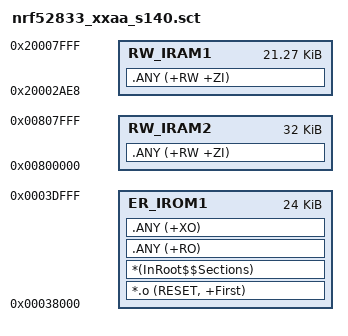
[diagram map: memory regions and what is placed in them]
; *************************************************************
; *** Scatter-Loading Description File generated by uVision ***
; *************************************************************

LR_IROM1 0x00038000 0x00006000  {    ; load region size_region
  ER_IROM1 0x00038000 0x00006000  {  ; load address = execution address
   *.o (RESET, +First)
   *(InRoot$$Sections)
   .ANY (+RO)
   .ANY (+XO)
  }
  RW_IRAM1 0x20002AE8 0x00005518  {  ; RW data
   .ANY (+RW +ZI)
  }
  RW_IRAM2 0x00800000 0x00008000  {
   .ANY (+RW +ZI)
  }
}

